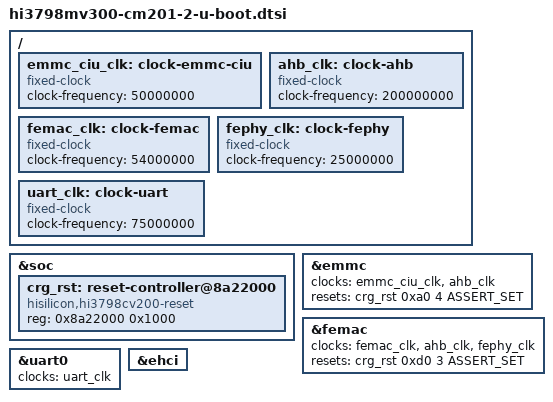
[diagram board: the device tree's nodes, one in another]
// SPDX-License-Identifier: GPL-2.0+
/*
 * CM201-2 的 U-Boot 补充：用固定时钟顶替 U-Boot 没有的 CRG 时钟驱动，CRG 复位位经 HiSilicon reset 驱动操作。
 *
 * 这里每个固定速率都必须与 board_init() 在 CRG 中设置（或保留）的值一致；复位 cell 的格式是 CRG 块内的 <offset bit polarity>。
 */

#include "hi3798mv200-u-boot.dtsi"

/ {
	/* PERI_CRG40 mux 1（50 MHz），由 board_init() 设置。 */
	emmc_ciu_clk: clock-emmc-ciu {
		compatible = "fixed-clock";
		#clock-cells = <0>;
		clock-frequency = <50000000>;
	};

	/* 供给 eMMC BIU 与 FEMAC 接口的 AHB 时钟。 */
	ahb_clk: clock-ahb {
		compatible = "fixed-clock";
		#clock-cells = <0>;
		clock-frequency = <200000000>;
	};

	/* FEMAC 核心时钟，mux 保持厂商 fastboot 的设置。 */
	femac_clk: clock-femac {
		compatible = "fixed-clock";
		#clock-cells = <0>;
		clock-frequency = <54000000>;
	};

	fephy_clk: clock-fephy {
		compatible = "fixed-clock";
		#clock-cells = <0>;
		clock-frequency = <25000000>;
	};

	uart_clk: clock-uart {
		compatible = "fixed-clock";
		#clock-cells = <0>;
		clock-frequency = <75000000>;
	};
};

&soc {
	crg_rst: reset-controller@8a22000 {
		compatible = "hisilicon,hi3798cv200-reset";
		reg = <0x8a22000 0x1000>;
		#reset-cells = <3>;
	};
};

&emmc {
	clocks = <&emmc_ciu_clk>, <&ahb_clk>;
	clock-names = "ciu", "biu";
	resets = <&crg_rst 0xa0 4 ASSERT_SET>;
	reset-names = "reset";
};

/*
 * 不写 PHY 复位：厂商 fastboot 刚为它自己的 TFTP 阶段用过 FE PHY，U-Boot 启动时链路已经建立。打一次 PHY 复位脉冲（CRG 0x388 bit 4）会让主机探测在发出 ARP 之前先等一次新的自动协商，约 2 s。
 */
&femac {
	clocks = <&femac_clk>, <&ahb_clk>, <&fephy_clk>;
	clock-names = "mac", "bus", "phy";
	resets = <&crg_rst 0xd0 3 ASSERT_SET>;
	reset-names = "mac";
};

&uart0 {
	clocks = <&uart_clk>;
	clock-names = "apb_pclk";
};

/*
 * EHCI 的时钟、复位与 INNO PHY 全部由 board_init() 打开（board/cmcc/cm201-2/cm201-2.c）：U-Boot 没有 CRG 时钟驱动，也没有这个 PHY 的驱动，而 PHY 的初始化要夹在控制器复位释放与端口复位释放之间，拆给 DM 做就排不出这个顺序。去掉这些属性后 generic-ehci 只管控制器本身。
 */
&ehci {
	/delete-property/ clocks;
	/delete-property/ clock-names;
	/delete-property/ resets;
	/delete-property/ reset-names;
	/delete-property/ phys;
	/delete-property/ phy-names;
};
